# MKV10Z1287 register map
Vendor: Freescale Semiconductor, Inc.; Series: Kinetis_V; File version: 1.6
CPU: CM0PLUS r0p0, little endian, no MPU, no FPU, VTOR, 2 interrupt priority bits
Registers are 32-bit, read-write, reset 0x0 unless marked. A register's access mark holds for its fields unless they carry their own. Offsets are from the block's base; [hi:lo] are bit positions.

## NVIC — Nested Vectored Interrupt Controller
Base 0xE000E100
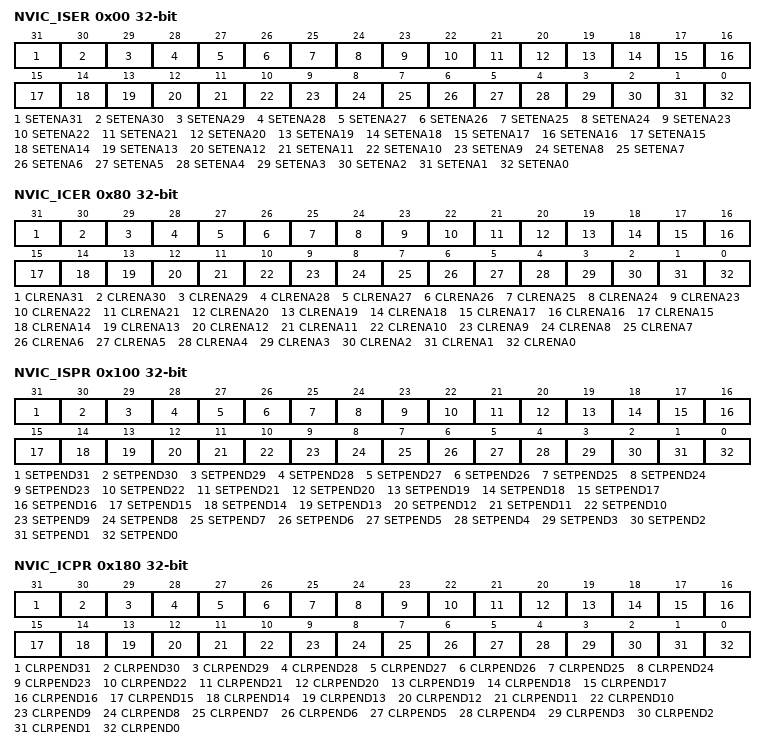
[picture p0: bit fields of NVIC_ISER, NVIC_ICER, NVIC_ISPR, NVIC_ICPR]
0x00 NVIC_ISER — Interrupt Set Enable Register
  [31] SETENA31 — PORTB, PORTC, PORTD and PORTE pin detect interrupt set-enable bit
    0=write: no effect; read: PORTB, PORTC, PORTD and PORTE pin detect interrupt disabled; 1=write: enable PORTB, PORTC, PORTD and PORTE pin detect interrupt; read: PORTB, PORTC, PORTD and PORTE pin detect interrupt enabled
  [30] SETENA30 — PORTA pin detect interrupt set-enable bit
    0=write: no effect; read: PORTA pin detect interrupt disabled; 1=write: enable PORTA pin detect interrupt; read: PORTA pin detect interrupt enabled
  [29] SETENA29 — single interrupt vector for programmable delay block 0 and 1 interrupt set-enable bit
    0=write: no effect; read: single interrupt vector for programmable delay block 0 and 1 interrupt disabled; 1=write: enable single interrupt vector for programmable delay block 0 and 1 interrupt; read: single interrupt vector for programmable delay block 0 and 1 interrupt enabled
  [28] SETENA28 — Low-Power Timer interrupt set-enable bit
    0=write: no effect; read: Low-Power Timer interrupt disabled; 1=write: enable Low-Power Timer interrupt; read: Low-Power Timer interrupt enabled
  [27] SETENA27 — multipurpose clock generator interrupt set-enable bit
    0=write: no effect; read: multipurpose clock generator interrupt disabled; 1=write: enable multipurpose clock generator interrupt; read: multipurpose clock generator interrupt enabled
  [26] SETENA26 — FlexTimer module 5 fault, overflow and channels interrupt set-enable bit
    0=write: no effect; read: FlexTimer module 5 fault, overflow and channels interrupt disabled; 1=write: enable FlexTimer module 5 fault, overflow and channels interrupt; read: FlexTimer module 5 fault, overflow and channels interrupt enabled
  [25] SETENA25 — digital-to-analog converter 0 interrupt set-enable bit
    0=write: no effect; read: digital-to-analog converter 0 interrupt disabled; 1=write: enable digital-to-analog converter 0 interrupt; read: digital-to-analog converter 0 interrupt enabled
  [24] SETENA24 — FlexTimer module 4 fault, overflow and channels interrupt set-enable bit
    0=write: no effect; read: FlexTimer module 4 fault, overflow and channels interrupt disabled; 1=write: enable FlexTimer module 4 fault, overflow and channels interrupt; read: FlexTimer module 4 fault, overflow and channels interrupt enabled
  [23] SETENA23 — single interrupt vector for WDOG and EWM interrupt set-enable bit
    0=write: no effect; read: single interrupt vector for WDOG and EWM interrupt disabled; 1=write: enable single interrupt vector for WDOG and EWM interrupt; read: single interrupt vector for WDOG and EWM interrupt enabled
  [22] SETENA22 — FlexTimer module 3 fault, overflow and channels interrupt set-enable bit
    0=write: no effect; read: FlexTimer module 3 fault, overflow and channels interrupt disabled; 1=write: enable FlexTimer module 3 fault, overflow and channels interrupt; read: FlexTimer module 3 fault, overflow and channels interrupt enabled
  [21] SETENA21 — Comparator 1 interrupt set-enable bit
    0=write: no effect; read: Comparator 1 interrupt disabled; 1=write: enable Comparator 1 interrupt; read: Comparator 1 interrupt enabled
  [20] SETENA20 — Comparator 0 interrupt set-enable bit
    0=write: no effect; read: Comparator 0 interrupt disabled; 1=write: enable Comparator 0 interrupt; read: Comparator 0 interrupt enabled
  [19] SETENA19 — FlexTimer module 2 fault, overflow and channels interrupt set-enable bit
    0=write: no effect; read: FlexTimer module 2 fault, overflow and channels interrupt disabled; 1=write: enable FlexTimer module 2 fault, overflow and channels interrupt; read: FlexTimer module 2 fault, overflow and channels interrupt enabled
  [18] SETENA18 — FlexTimer module 1 fault, overflow and channels interrupt set-enable bit
    0=write: no effect; read: FlexTimer module 1 fault, overflow and channels interrupt disabled; 1=write: enable FlexTimer module 1 fault, overflow and channels interrupt; read: FlexTimer module 1 fault, overflow and channels interrupt enabled
  [17] SETENA17 — FlexTimer module 0 fault, overflow and channels interrupt set-enable bit
    0=write: no effect; read: FlexTimer module 0 fault, overflow and channels interrupt disabled; 1=write: enable FlexTimer module 0 fault, overflow and channels interrupt; read: FlexTimer module 0 fault, overflow and channels interrupt enabled
  [16] SETENA16 — Analog-to-digital converter 1 interrupt set-enable bit
    0=write: no effect; read: Analog-to-digital converter 1 interrupt disabled; 1=write: enable Analog-to-digital converter 1 interrupt; read: Analog-to-digital converter 1 interrupt enabled
  [15] SETENA15 — Analog-to-digital converter 0 interrupt set-enable bit
    0=write: no effect; read: Analog-to-digital converter 0 interrupt disabled; 1=write: enable Analog-to-digital converter 0 interrupt; read: Analog-to-digital converter 0 interrupt enabled
  [14] SETENA14 — Reserved iv 30 interrupt set-enable bit
    0=write: no effect; read: Reserved iv 30 interrupt disabled; 1=write: enable Reserved iv 30 interrupt; read: Reserved iv 30 interrupt enabled
  [13] SETENA13 — UART1 status and error interrupt set-enable bit
    0=write: no effect; read: UART1 status and error interrupt disabled; 1=write: enable UART1 status and error interrupt; read: UART1 status and error interrupt enabled
  [12] SETENA12 — UART0 status and error interrupt set-enable bit
    0=write: no effect; read: UART0 status and error interrupt disabled; 1=write: enable UART0 status and error interrupt; read: UART0 status and error interrupt enabled
  [11] SETENA11 — Reserved iv 27 interrupt set-enable bit
    0=write: no effect; read: Reserved iv 27 interrupt disabled; 1=write: enable Reserved iv 27 interrupt; read: Reserved iv 27 interrupt enabled
  [10] SETENA10 — serial peripheral interface 0 interrupt set-enable bit
    0=write: no effect; read: serial peripheral interface 0 interrupt disabled; 1=write: enable serial peripheral interface 0 interrupt; read: serial peripheral interface 0 interrupt enabled
  [9] SETENA9 — Reserved iv 25 interrupt set-enable bit
    0=write: no effect; read: Reserved iv 25 interrupt disabled; 1=write: enable Reserved iv 25 interrupt; read: Reserved iv 25 interrupt enabled
  [8] SETENA8 — inter-integrated circuit 0 interrupt set-enable bit
    0=write: no effect; read: inter-integrated circuit 0 interrupt disabled; 1=write: enable inter-integrated circuit 0 interrupt; read: inter-integrated circuit 0 interrupt enabled
  [7] SETENA7 — low leakage wakeup interrupt set-enable bit
    0=write: no effect; read: low leakage wakeup interrupt disabled; 1=write: enable low leakage wakeup interrupt; read: low leakage wakeup interrupt enabled
  [6] SETENA6 — low-voltage detect and low-voltage warning interrupt set-enable bit
    0=write: no effect; read: low-voltage detect and low-voltage warning interrupt disabled; 1=write: enable low-voltage detect and low-voltage warning interrupt; read: low-voltage detect and low-voltage warning interrupt enabled
  [5] SETENA5 — FTFA command complete and read collision interrupt set-enable bit
    0=write: no effect; read: FTFA command complete and read collision interrupt disabled; 1=write: enable FTFA command complete and read collision interrupt; read: FTFA command complete and read collision interrupt enabled
  [4] SETENA4 — DMA error interrupt channels 0-7 interrupt set-enable bit
    0=write: no effect; read: DMA error interrupt channels 0-7 interrupt disabled; 1=write: enable DMA error interrupt channels 0-7 interrupt; read: DMA error interrupt channels 0-7 interrupt enabled
  [3] SETENA3 — DMA channel 2 and 7 transfer complete interrupt set-enable bit
    0=write: no effect; read: DMA channel 2 and 7 transfer complete interrupt disabled; 1=write: enable DMA channel 2 and 7 transfer complete interrupt; read: DMA channel 2 and 7 transfer complete interrupt enabled
  [2] SETENA2 — DMA channel 2 and 6 transfer complete interrupt set-enable bit
    0=write: no effect; read: DMA channel 2 and 6 transfer complete interrupt disabled; 1=write: enable DMA channel 2 and 6 transfer complete interrupt; read: DMA channel 2 and 6 transfer complete interrupt enabled
  [1] SETENA1 — DMA channel 1 and 5 transfer complete interrupt set-enable bit
    0=write: no effect; read: DMA channel 1 and 5 transfer complete interrupt disabled; 1=write: enable DMA channel 1 and 5 transfer complete interrupt; read: DMA channel 1 and 5 transfer complete interrupt enabled
  [0] SETENA0 — DMA channel 0 and 4 transfer complete interrupt set-enable bit
    0=write: no effect; read: DMA channel 0 and 4 transfer complete interrupt disabled; 1=write: enable DMA channel 0 and 4 transfer complete interrupt; read: DMA channel 0 and 4 transfer complete interrupt enabled
0x80 NVIC_ICER — Interrupt Clear Enable Register
  [31] CLRENA31 — PORTB, PORTC, PORTD and PORTE pin detect interrupt clear-enable bit
    0=write: no effect; read: PORTB, PORTC, PORTD and PORTE pin detect interrupt disabled; 1=write: disable PORTB, PORTC, PORTD and PORTE pin detect interrupt; read: PORTB, PORTC, PORTD and PORTE pin detect interrupt enabled
  [30] CLRENA30 — PORTA pin detect interrupt clear-enable bit
    0=write: no effect; read: PORTA pin detect interrupt disabled; 1=write: disable PORTA pin detect interrupt; read: PORTA pin detect interrupt enabled
  [29] CLRENA29 — single interrupt vector for programmable delay block 0 and 1 interrupt clear-enable bit
    0=write: no effect; read: single interrupt vector for programmable delay block 0 and 1 interrupt disabled; 1=write: disable single interrupt vector for programmable delay block 0 and 1 interrupt; read: single interrupt vector for programmable delay block 0 and 1 interrupt enabled
  [28] CLRENA28 — Low-Power Timer interrupt clear-enable bit
    0=write: no effect; read: Low-Power Timer interrupt disabled; 1=write: disable Low-Power Timer interrupt; read: Low-Power Timer interrupt enabled
  [27] CLRENA27 — multipurpose clock generator interrupt clear-enable bit
    0=write: no effect; read: multipurpose clock generator interrupt disabled; 1=write: disable multipurpose clock generator interrupt; read: multipurpose clock generator interrupt enabled
  [26] CLRENA26 — FlexTimer module 5 fault, overflow and channels interrupt clear-enable bit
    0=write: no effect; read: FlexTimer module 5 fault, overflow and channels interrupt disabled; 1=write: disable FlexTimer module 5 fault, overflow and channels interrupt; read: FlexTimer module 5 fault, overflow and channels interrupt enabled
  [25] CLRENA25 — digital-to-analog converter 0 interrupt clear-enable bit
    0=write: no effect; read: digital-to-analog converter 0 interrupt disabled; 1=write: disable digital-to-analog converter 0 interrupt; read: digital-to-analog converter 0 interrupt enabled
  [24] CLRENA24 — FlexTimer module 4 fault, overflow and channels interrupt clear-enable bit
    0=write: no effect; read: FlexTimer module 4 fault, overflow and channels interrupt disabled; 1=write: disable FlexTimer module 4 fault, overflow and channels interrupt; read: FlexTimer module 4 fault, overflow and channels interrupt enabled
  [23] CLRENA23 — single interrupt vector for WDOG and EWM interrupt clear-enable bit
    0=write: no effect; read: single interrupt vector for WDOG and EWM interrupt disabled; 1=write: disable single interrupt vector for WDOG and EWM interrupt; read: single interrupt vector for WDOG and EWM interrupt enabled
  [22] CLRENA22 — FlexTimer module 3 fault, overflow and channels interrupt clear-enable bit
    0=write: no effect; read: FlexTimer module 3 fault, overflow and channels interrupt disabled; 1=write: disable FlexTimer module 3 fault, overflow and channels interrupt; read: FlexTimer module 3 fault, overflow and channels interrupt enabled
  [21] CLRENA21 — Comparator 1 interrupt clear-enable bit
    0=write: no effect; read: Comparator 1 interrupt disabled; 1=write: disable Comparator 1 interrupt; read: Comparator 1 interrupt enabled
  [20] CLRENA20 — Comparator 0 interrupt clear-enable bit
    0=write: no effect; read: Comparator 0 interrupt disabled; 1=write: disable Comparator 0 interrupt; read: Comparator 0 interrupt enabled
  [19] CLRENA19 — FlexTimer module 2 fault, overflow and channels interrupt clear-enable bit
    0=write: no effect; read: FlexTimer module 2 fault, overflow and channels interrupt disabled; 1=write: disable FlexTimer module 2 fault, overflow and channels interrupt; read: FlexTimer module 2 fault, overflow and channels interrupt enabled
  [18] CLRENA18 — FlexTimer module 1 fault, overflow and channels interrupt clear-enable bit
    0=write: no effect; read: FlexTimer module 1 fault, overflow and channels interrupt disabled; 1=write: disable FlexTimer module 1 fault, overflow and channels interrupt; read: FlexTimer module 1 fault, overflow and channels interrupt enabled
  [17] CLRENA17 — FlexTimer module 0 fault, overflow and channels interrupt clear-enable bit
    0=write: no effect; read: FlexTimer module 0 fault, overflow and channels interrupt disabled; 1=write: disable FlexTimer module 0 fault, overflow and channels interrupt; read: FlexTimer module 0 fault, overflow and channels interrupt enabled
  [16] CLRENA16 — Analog-to-digital converter 1 interrupt clear-enable bit
    0=write: no effect; read: Analog-to-digital converter 1 interrupt disabled; 1=write: disable Analog-to-digital converter 1 interrupt; read: Analog-to-digital converter 1 interrupt enabled
  [15] CLRENA15 — Analog-to-digital converter 0 interrupt clear-enable bit
    0=write: no effect; read: Analog-to-digital converter 0 interrupt disabled; 1=write: disable Analog-to-digital converter 0 interrupt; read: Analog-to-digital converter 0 interrupt enabled
  [14] CLRENA14 — Reserved iv 30 interrupt clear-enable bit
    0=write: no effect; read: Reserved iv 30 interrupt disabled; 1=write: disable Reserved iv 30 interrupt; read: Reserved iv 30 interrupt enabled
  [13] CLRENA13 — UART1 status and error interrupt clear-enable bit
    0=write: no effect; read: UART1 status and error interrupt disabled; 1=write: disable UART1 status and error interrupt; read: UART1 status and error interrupt enabled
  [12] CLRENA12 — UART0 status and error interrupt clear-enable bit
    0=write: no effect; read: UART0 status and error interrupt disabled; 1=write: disable UART0 status and error interrupt; read: UART0 status and error interrupt enabled
  [11] CLRENA11 — Reserved iv 27 interrupt clear-enable bit
    0=write: no effect; read: Reserved iv 27 interrupt disabled; 1=write: disable Reserved iv 27 interrupt; read: Reserved iv 27 interrupt enabled
  [10] CLRENA10 — serial peripheral interface 0 interrupt clear-enable bit
    0=write: no effect; read: serial peripheral interface 0 interrupt disabled; 1=write: disable serial peripheral interface 0 interrupt; read: serial peripheral interface 0 interrupt enabled
  [9] CLRENA9 — Reserved iv 25 interrupt clear-enable bit
    0=write: no effect; read: Reserved iv 25 interrupt disabled; 1=write: disable Reserved iv 25 interrupt; read: Reserved iv 25 interrupt enabled
  [8] CLRENA8 — inter-integrated circuit 0 interrupt clear-enable bit
    0=write: no effect; read: inter-integrated circuit 0 interrupt disabled; 1=write: disable inter-integrated circuit 0 interrupt; read: inter-integrated circuit 0 interrupt enabled
  [7] CLRENA7 — low leakage wakeup interrupt clear-enable bit
    0=write: no effect; read: low leakage wakeup interrupt disabled; 1=write: disable low leakage wakeup interrupt; read: low leakage wakeup interrupt enabled
  [6] CLRENA6 — low-voltage detect and low-voltage warning interrupt clear-enable bit
    0=write: no effect; read: low-voltage detect and low-voltage warning interrupt disabled; 1=write: disable low-voltage detect and low-voltage warning interrupt; read: low-voltage detect and low-voltage warning interrupt enabled
  [5] CLRENA5 — FTFA command complete and read collision interrupt clear-enable bit
    0=write: no effect; read: FTFA command complete and read collision interrupt disabled; 1=write: disable FTFA command complete and read collision interrupt; read: FTFA command complete and read collision interrupt enabled
  [4] CLRENA4 — DMA error interrupt channels 0-7 interrupt clear-enable bit
    0=write: no effect; read: DMA error interrupt channels 0-7 interrupt disabled; 1=write: disable DMA error interrupt channels 0-7 interrupt; read: DMA error interrupt channels 0-7 interrupt enabled
  [3] CLRENA3 — DMA channel 2 and 7 transfer complete interrupt clear-enable bit
    0=write: no effect; read: DMA channel 2 and 7 transfer complete interrupt disabled; 1=write: disable DMA channel 2 and 7 transfer complete interrupt; read: DMA channel 2 and 7 transfer complete interrupt enabled
  [2] CLRENA2 — DMA channel 2 and 6 transfer complete interrupt clear-enable bit
    0=write: no effect; read: DMA channel 2 and 6 transfer complete interrupt disabled; 1=write: disable DMA channel 2 and 6 transfer complete interrupt; read: DMA channel 2 and 6 transfer complete interrupt enabled
  [1] CLRENA1 — DMA channel 1 and 5 transfer complete interrupt clear-enable bit
    0=write: no effect; read: DMA channel 1 and 5 transfer complete interrupt disabled; 1=write: disable DMA channel 1 and 5 transfer complete interrupt; read: DMA channel 1 and 5 transfer complete interrupt enabled
  [0] CLRENA0 — DMA channel 0 and 4 transfer complete interrupt clear-enable bit
    0=write: no effect; read: DMA channel 0 and 4 transfer complete interrupt disabled; 1=write: disable DMA channel 0 and 4 transfer complete interrupt; read: DMA channel 0 and 4 transfer complete interrupt enabled
0x100 NVIC_ISPR — Interrupt Set Pending Register
  [31] SETPEND31 — PORTB, PORTC, PORTD and PORTE pin detect interrupt set-pending bit
    0=write: no effect; read: PORTB, PORTC, PORTD and PORTE pin detect interrupt is not pending; 1=write: changes the PORTB, PORTC, PORTD and PORTE pin detect interrupt state to pending; read: PORTB, PORTC, PORTD and PORTE pin detect interrupt is pending
  [30] SETPEND30 — PORTA pin detect interrupt set-pending bit
    0=write: no effect; read: PORTA pin detect interrupt is not pending; 1=write: changes the PORTA pin detect interrupt state to pending; read: PORTA pin detect interrupt is pending
  [29] SETPEND29 — single interrupt vector for programmable delay block 0 and 1 interrupt set-pending bit
    0=write: no effect; read: single interrupt vector for programmable delay block 0 and 1 interrupt is not pending; 1=write: changes the single interrupt vector for programmable delay block 0 and 1 interrupt state to pending; read: single interrupt vector for programmable delay block 0 and 1 interrupt is pending
  [28] SETPEND28 — Low-Power Timer interrupt set-pending bit
    0=write: no effect; read: Low-Power Timer interrupt is not pending; 1=write: changes the Low-Power Timer interrupt state to pending; read: Low-Power Timer interrupt is pending
  [27] SETPEND27 — multipurpose clock generator interrupt set-pending bit
    0=write: no effect; read: multipurpose clock generator interrupt is not pending; 1=write: changes the multipurpose clock generator interrupt state to pending; read: multipurpose clock generator interrupt is pending
  [26] SETPEND26 — FlexTimer module 5 fault, overflow and channels interrupt set-pending bit
    0=write: no effect; read: FlexTimer module 5 fault, overflow and channels interrupt is not pending; 1=write: changes the FlexTimer module 5 fault, overflow and channels interrupt state to pending; read: FlexTimer module 5 fault, overflow and channels interrupt is pending
  [25] SETPEND25 — digital-to-analog converter 0 interrupt set-pending bit
    0=write: no effect; read: digital-to-analog converter 0 interrupt is not pending; 1=write: changes the digital-to-analog converter 0 interrupt state to pending; read: digital-to-analog converter 0 interrupt is pending
  [24] SETPEND24 — FlexTimer module 4 fault, overflow and channels interrupt set-pending bit
    0=write: no effect; read: FlexTimer module 4 fault, overflow and channels interrupt is not pending; 1=write: changes the FlexTimer module 4 fault, overflow and channels interrupt state to pending; read: FlexTimer module 4 fault, overflow and channels interrupt is pending
  [23] SETPEND23 — single interrupt vector for WDOG and EWM interrupt set-pending bit
    0=write: no effect; read: single interrupt vector for WDOG and EWM interrupt is not pending; 1=write: changes the single interrupt vector for WDOG and EWM interrupt state to pending; read: single interrupt vector for WDOG and EWM interrupt is pending
  [22] SETPEND22 — FlexTimer module 3 fault, overflow and channels interrupt set-pending bit
    0=write: no effect; read: FlexTimer module 3 fault, overflow and channels interrupt is not pending; 1=write: changes the FlexTimer module 3 fault, overflow and channels interrupt state to pending; read: FlexTimer module 3 fault, overflow and channels interrupt is pending
  [21] SETPEND21 — Comparator 1 interrupt set-pending bit
    0=write: no effect; read: Comparator 1 interrupt is not pending; 1=write: changes the Comparator 1 interrupt state to pending; read: Comparator 1 interrupt is pending
  [20] SETPEND20 — Comparator 0 interrupt set-pending bit
    0=write: no effect; read: Comparator 0 interrupt is not pending; 1=write: changes the Comparator 0 interrupt state to pending; read: Comparator 0 interrupt is pending
  [19] SETPEND19 — FlexTimer module 2 fault, overflow and channels interrupt set-pending bit
    0=write: no effect; read: FlexTimer module 2 fault, overflow and channels interrupt is not pending; 1=write: changes the FlexTimer module 2 fault, overflow and channels interrupt state to pending; read: FlexTimer module 2 fault, overflow and channels interrupt is pending
  [18] SETPEND18 — FlexTimer module 1 fault, overflow and channels interrupt set-pending bit
    0=write: no effect; read: FlexTimer module 1 fault, overflow and channels interrupt is not pending; 1=write: changes the FlexTimer module 1 fault, overflow and channels interrupt state to pending; read: FlexTimer module 1 fault, overflow and channels interrupt is pending
  [17] SETPEND17 — FlexTimer module 0 fault, overflow and channels interrupt set-pending bit
    0=write: no effect; read: FlexTimer module 0 fault, overflow and channels interrupt is not pending; 1=write: changes the FlexTimer module 0 fault, overflow and channels interrupt state to pending; read: FlexTimer module 0 fault, overflow and channels interrupt is pending
  [16] SETPEND16 — Analog-to-digital converter 1 interrupt set-pending bit
    0=write: no effect; read: Analog-to-digital converter 1 interrupt is not pending; 1=write: changes the Analog-to-digital converter 1 interrupt state to pending; read: Analog-to-digital converter 1 interrupt is pending
  [15] SETPEND15 — Analog-to-digital converter 0 interrupt set-pending bit
    0=write: no effect; read: Analog-to-digital converter 0 interrupt is not pending; 1=write: changes the Analog-to-digital converter 0 interrupt state to pending; read: Analog-to-digital converter 0 interrupt is pending
  [14] SETPEND14 — Reserved iv 30 interrupt set-pending bit
    0=write: no effect; read: Reserved iv 30 interrupt is not pending; 1=write: changes the Reserved iv 30 interrupt state to pending; read: Reserved iv 30 interrupt is pending
  [13] SETPEND13 — UART1 status and error interrupt set-pending bit
    0=write: no effect; read: UART1 status and error interrupt is not pending; 1=write: changes the UART1 status and error interrupt state to pending; read: UART1 status and error interrupt is pending
  [12] SETPEND12 — UART0 status and error interrupt set-pending bit
    0=write: no effect; read: UART0 status and error interrupt is not pending; 1=write: changes the UART0 status and error interrupt state to pending; read: UART0 status and error interrupt is pending
  [11] SETPEND11 — Reserved iv 27 interrupt set-pending bit
    0=write: no effect; read: Reserved iv 27 interrupt is not pending; 1=write: changes the Reserved iv 27 interrupt state to pending; read: Reserved iv 27 interrupt is pending
  [10] SETPEND10 — serial peripheral interface 0 interrupt set-pending bit
    0=write: no effect; read: serial peripheral interface 0 interrupt is not pending; 1=write: changes the serial peripheral interface 0 interrupt state to pending; read: serial peripheral interface 0 interrupt is pending
  [9] SETPEND9 — Reserved iv 25 interrupt set-pending bit
    0=write: no effect; read: Reserved iv 25 interrupt is not pending; 1=write: changes the Reserved iv 25 interrupt state to pending; read: Reserved iv 25 interrupt is pending
  [8] SETPEND8 — inter-integrated circuit 0 interrupt set-pending bit
    0=write: no effect; read: inter-integrated circuit 0 interrupt is not pending; 1=write: changes the inter-integrated circuit 0 interrupt state to pending; read: inter-integrated circuit 0 interrupt is pending
  [7] SETPEND7 — low leakage wakeup interrupt set-pending bit
    0=write: no effect; read: low leakage wakeup interrupt is not pending; 1=write: changes the low leakage wakeup interrupt state to pending; read: low leakage wakeup interrupt is pending
  [6] SETPEND6 — low-voltage detect and low-voltage warning interrupt set-pending bit
    0=write: no effect; read: low-voltage detect and low-voltage warning interrupt is not pending; 1=write: changes the low-voltage detect and low-voltage warning interrupt state to pending; read: low-voltage detect and low-voltage warning interrupt is pending
  [5] SETPEND5 — FTFA command complete and read collision interrupt set-pending bit
    0=write: no effect; read: FTFA command complete and read collision interrupt is not pending; 1=write: changes the FTFA command complete and read collision interrupt state to pending; read: FTFA command complete and read collision interrupt is pending
  [4] SETPEND4 — DMA error interrupt channels 0-7 interrupt set-pending bit
    0=write: no effect; read: DMA error interrupt channels 0-7 interrupt is not pending; 1=write: changes the DMA error interrupt channels 0-7 interrupt state to pending; read: DMA error interrupt channels 0-7 interrupt is pending
  [3] SETPEND3 — DMA channel 2 and 7 transfer complete interrupt set-pending bit
    0=write: no effect; read: DMA channel 2 and 7 transfer complete interrupt is not pending; 1=write: changes the DMA channel 2 and 7 transfer complete interrupt state to pending; read: DMA channel 2 and 7 transfer complete interrupt is pending
  [2] SETPEND2 — DMA channel 2 and 6 transfer complete interrupt set-pending bit
    0=write: no effect; read: DMA channel 2 and 6 transfer complete interrupt is not pending; 1=write: changes the DMA channel 2 and 6 transfer complete interrupt state to pending; read: DMA channel 2 and 6 transfer complete interrupt is pending
  [1] SETPEND1 — DMA channel 1 and 5 transfer complete interrupt set-pending bit
    0=write: no effect; read: DMA channel 1 and 5 transfer complete interrupt is not pending; 1=write: changes the DMA channel 1 and 5 transfer complete interrupt state to pending; read: DMA channel 1 and 5 transfer complete interrupt is pending
  [0] SETPEND0 — DMA channel 0 and 4 transfer complete interrupt set-pending bit
    0=write: no effect; read: DMA channel 0 and 4 transfer complete interrupt is not pending; 1=write: changes the DMA channel 0 and 4 transfer complete interrupt state to pending; read: DMA channel 0 and 4 transfer complete interrupt is pending
0x180 NVIC_ICPR — Interrupt Clear Pending Register
  [31] CLRPEND31 — PORTB, PORTC, PORTD and PORTE pin detect interrupt clear-pending bit
    0=write: no effect; read: PORTB, PORTC, PORTD and PORTE pin detect interrupt is not pending; 1=write: removes pending state from the PORTB, PORTC, PORTD and PORTE pin detect interrupt; read: PORTB, PORTC, PORTD and PORTE pin detect interrupt is pending
  [30] CLRPEND30 — PORTA pin detect interrupt clear-pending bit
    0=write: no effect; read: PORTA pin detect interrupt is not pending; 1=write: removes pending state from the PORTA pin detect interrupt; read: PORTA pin detect interrupt is pending
  [29] CLRPEND29 — single interrupt vector for programmable delay block 0 and 1 interrupt clear-pending bit
    0=write: no effect; read: single interrupt vector for programmable delay block 0 and 1 interrupt is not pending; 1=write: removes pending state from the single interrupt vector for programmable delay block 0 and 1 interrupt; read: single interrupt vector for programmable delay block 0 and 1 interrupt is pending
  [28] CLRPEND28 — Low-Power Timer interrupt clear-pending bit
    0=write: no effect; read: Low-Power Timer interrupt is not pending; 1=write: removes pending state from the Low-Power Timer interrupt; read: Low-Power Timer interrupt is pending
  [27] CLRPEND27 — multipurpose clock generator interrupt clear-pending bit
    0=write: no effect; read: multipurpose clock generator interrupt is not pending; 1=write: removes pending state from the multipurpose clock generator interrupt; read: multipurpose clock generator interrupt is pending
  [26] CLRPEND26 — FlexTimer module 5 fault, overflow and channels interrupt clear-pending bit
    0=write: no effect; read: FlexTimer module 5 fault, overflow and channels interrupt is not pending; 1=write: removes pending state from the FlexTimer module 5 fault, overflow and channels interrupt; read: FlexTimer module 5 fault, overflow and channels interrupt is pending
  [25] CLRPEND25 — digital-to-analog converter 0 interrupt clear-pending bit
    0=write: no effect; read: digital-to-analog converter 0 interrupt is not pending; 1=write: removes pending state from the digital-to-analog converter 0 interrupt; read: digital-to-analog converter 0 interrupt is pending
  [24] CLRPEND24 — FlexTimer module 4 fault, overflow and channels interrupt clear-pending bit
    0=write: no effect; read: FlexTimer module 4 fault, overflow and channels interrupt is not pending; 1=write: removes pending state from the FlexTimer module 4 fault, overflow and channels interrupt; read: FlexTimer module 4 fault, overflow and channels interrupt is pending
  [23] CLRPEND23 — single interrupt vector for WDOG and EWM interrupt clear-pending bit
    0=write: no effect; read: single interrupt vector for WDOG and EWM interrupt is not pending; 1=write: removes pending state from the single interrupt vector for WDOG and EWM interrupt; read: single interrupt vector for WDOG and EWM interrupt is pending
  [22] CLRPEND22 — FlexTimer module 3 fault, overflow and channels interrupt clear-pending bit
    0=write: no effect; read: FlexTimer module 3 fault, overflow and channels interrupt is not pending; 1=write: removes pending state from the FlexTimer module 3 fault, overflow and channels interrupt; read: FlexTimer module 3 fault, overflow and channels interrupt is pending
  [21] CLRPEND21 — Comparator 1 interrupt clear-pending bit
    0=write: no effect; read: Comparator 1 interrupt is not pending; 1=write: removes pending state from the Comparator 1 interrupt; read: Comparator 1 interrupt is pending
  [20] CLRPEND20 — Comparator 0 interrupt clear-pending bit
    0=write: no effect; read: Comparator 0 interrupt is not pending; 1=write: removes pending state from the Comparator 0 interrupt; read: Comparator 0 interrupt is pending
  [19] CLRPEND19 — FlexTimer module 2 fault, overflow and channels interrupt clear-pending bit
    0=write: no effect; read: FlexTimer module 2 fault, overflow and channels interrupt is not pending; 1=write: removes pending state from the FlexTimer module 2 fault, overflow and channels interrupt; read: FlexTimer module 2 fault, overflow and channels interrupt is pending
  [18] CLRPEND18 — FlexTimer module 1 fault, overflow and channels interrupt clear-pending bit
    0=write: no effect; read: FlexTimer module 1 fault, overflow and channels interrupt is not pending; 1=write: removes pending state from the FlexTimer module 1 fault, overflow and channels interrupt; read: FlexTimer module 1 fault, overflow and channels interrupt is pending
  [17] CLRPEND17 — FlexTimer module 0 fault, overflow and channels interrupt clear-pending bit
    0=write: no effect; read: FlexTimer module 0 fault, overflow and channels interrupt is not pending; 1=write: removes pending state from the FlexTimer module 0 fault, overflow and channels interrupt; read: FlexTimer module 0 fault, overflow and channels interrupt is pending
  [16] CLRPEND16 — Analog-to-digital converter 1 interrupt clear-pending bit
    0=write: no effect; read: Analog-to-digital converter 1 interrupt is not pending; 1=write: removes pending state from the Analog-to-digital converter 1 interrupt; read: Analog-to-digital converter 1 interrupt is pending
  [15] CLRPEND15 — Analog-to-digital converter 0 interrupt clear-pending bit
    0=write: no effect; read: Analog-to-digital converter 0 interrupt is not pending; 1=write: removes pending state from the Analog-to-digital converter 0 interrupt; read: Analog-to-digital converter 0 interrupt is pending
  [14] CLRPEND14 — Reserved iv 30 interrupt clear-pending bit
    0=write: no effect; read: Reserved iv 30 interrupt is not pending; 1=write: removes pending state from the Reserved iv 30 interrupt; read: Reserved iv 30 interrupt is pending
  [13] CLRPEND13 — UART1 status and error interrupt clear-pending bit
    0=write: no effect; read: UART1 status and error interrupt is not pending; 1=write: removes pending state from the UART1 status and error interrupt; read: UART1 status and error interrupt is pending
  [12] CLRPEND12 — UART0 status and error interrupt clear-pending bit
    0=write: no effect; read: UART0 status and error interrupt is not pending; 1=write: removes pending state from the UART0 status and error interrupt; read: UART0 status and error interrupt is pending
  [11] CLRPEND11 — Reserved iv 27 interrupt clear-pending bit
    0=write: no effect; read: Reserved iv 27 interrupt is not pending; 1=write: removes pending state from the Reserved iv 27 interrupt; read: Reserved iv 27 interrupt is pending
  [10] CLRPEND10 — serial peripheral interface 0 interrupt clear-pending bit
    0=write: no effect; read: serial peripheral interface 0 interrupt is not pending; 1=write: removes pending state from the serial peripheral interface 0 interrupt; read: serial peripheral interface 0 interrupt is pending
  [9] CLRPEND9 — Reserved iv 25 interrupt clear-pending bit
    0=write: no effect; read: Reserved iv 25 interrupt is not pending; 1=write: removes pending state from the Reserved iv 25 interrupt; read: Reserved iv 25 interrupt is pending
  [8] CLRPEND8 — inter-integrated circuit 0 interrupt clear-pending bit
    0=write: no effect; read: inter-integrated circuit 0 interrupt is not pending; 1=write: removes pending state from the inter-integrated circuit 0 interrupt; read: inter-integrated circuit 0 interrupt is pending
  [7] CLRPEND7 — low leakage wakeup interrupt clear-pending bit
    0=write: no effect; read: low leakage wakeup interrupt is not pending; 1=write: removes pending state from the low leakage wakeup interrupt; read: low leakage wakeup interrupt is pending
  [6] CLRPEND6 — low-voltage detect and low-voltage warning interrupt clear-pending bit
    0=write: no effect; read: low-voltage detect and low-voltage warning interrupt is not pending; 1=write: removes pending state from the low-voltage detect and low-voltage warning interrupt; read: low-voltage detect and low-voltage warning interrupt is pending
  [5] CLRPEND5 — FTFA command complete and read collision interrupt clear-pending bit
    0=write: no effect; read: FTFA command complete and read collision interrupt is not pending; 1=write: removes pending state from the FTFA command complete and read collision interrupt; read: FTFA command complete and read collision interrupt is pending
  [4] CLRPEND4 — DMA error interrupt channels 0-7 interrupt clear-pending bit
    0=write: no effect; read: DMA error interrupt channels 0-7 interrupt is not pending; 1=write: removes pending state from the DMA error interrupt channels 0-7 interrupt; read: DMA error interrupt channels 0-7 interrupt is pending
  [3] CLRPEND3 — DMA channel 2 and 7 transfer complete interrupt clear-pending bit
    0=write: no effect; read: DMA channel 2 and 7 transfer complete interrupt is not pending; 1=write: removes pending state from the DMA channel 2 and 7 transfer complete interrupt; read: DMA channel 2 and 7 transfer complete interrupt is pending
  [2] CLRPEND2 — DMA channel 2 and 6 transfer complete interrupt clear-pending bit
    0=write: no effect; read: DMA channel 2 and 6 transfer complete interrupt is not pending; 1=write: removes pending state from the DMA channel 2 and 6 transfer complete interrupt; read: DMA channel 2 and 6 transfer complete interrupt is pending
  [1] CLRPEND1 — DMA channel 1 and 5 transfer complete interrupt clear-pending bit
    0=write: no effect; read: DMA channel 1 and 5 transfer complete interrupt is not pending; 1=write: removes pending state from the DMA channel 1 and 5 transfer complete interrupt; read: DMA channel 1 and 5 transfer complete interrupt is pending
  [0] CLRPEND0 — DMA channel 0 and 4 transfer complete interrupt clear-pending bit
    0=write: no effect; read: DMA channel 0 and 4 transfer complete interrupt is not pending; 1=write: removes pending state from the DMA channel 0 and 4 transfer complete interrupt; read: DMA channel 0 and 4 transfer complete interrupt is pending
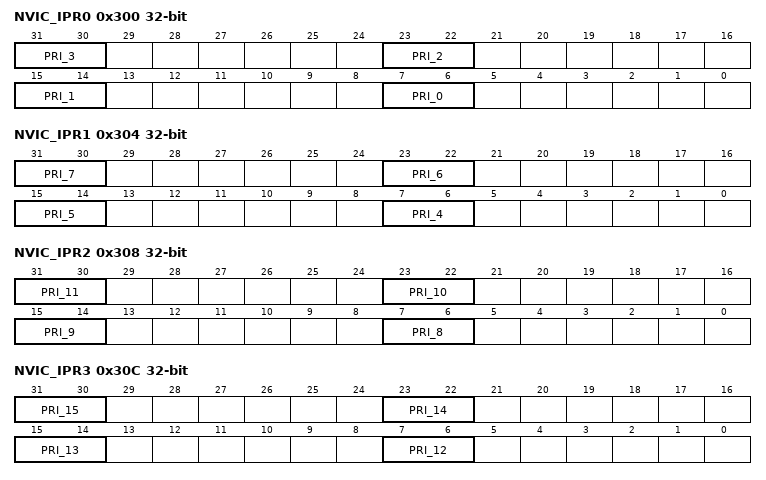
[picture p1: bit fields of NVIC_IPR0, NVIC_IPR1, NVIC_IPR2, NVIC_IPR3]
0x300 NVIC_IPR0 — Interrupt Priority Register 0
  [31:30] PRI_3 — Priority of the DMA channel 2 and 7 transfer complete interrupt
  [23:22] PRI_2 — Priority of the DMA channel 2 and 6 transfer complete interrupt
  [15:14] PRI_1 — Priority of the DMA channel 1 and 5 transfer complete interrupt
  [7:6] PRI_0 — Priority of the DMA channel 0 and 4 transfer complete interrupt
0x304 NVIC_IPR1 — Interrupt Priority Register 1
  [31:30] PRI_7 — Priority of the low leakage wakeup interrupt
  [23:22] PRI_6 — Priority of the low-voltage detect and low-voltage warning interrupt
  [15:14] PRI_5 — Priority of the FTFA command complete and read collision interrupt
  [7:6] PRI_4 — Priority of the DMA error interrupt channels 0-7 interrupt
0x308 NVIC_IPR2 — Interrupt Priority Register 2
  [31:30] PRI_11 — Priority of the Reserved iv 27 interrupt
  [23:22] PRI_10 — Priority of the serial peripheral interface 0 interrupt
  [15:14] PRI_9 — Priority of the Reserved iv 25 interrupt
  [7:6] PRI_8 — Priority of the inter-integrated circuit 0 interrupt
0x30C NVIC_IPR3 — Interrupt Priority Register 3
  [31:30] PRI_15 — Priority of the Analog-to-digital converter 0 interrupt
  [23:22] PRI_14 — Priority of the Reserved iv 30 interrupt
  [15:14] PRI_13 — Priority of the UART1 status and error interrupt
  [7:6] PRI_12 — Priority of the UART0 status and error interrupt
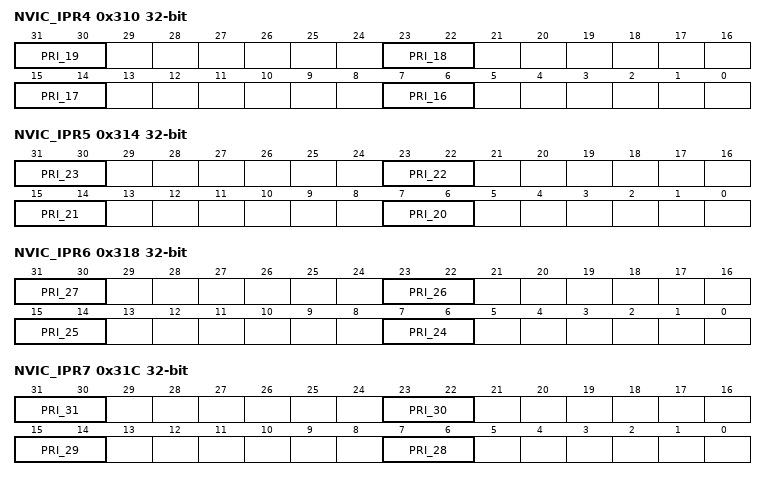
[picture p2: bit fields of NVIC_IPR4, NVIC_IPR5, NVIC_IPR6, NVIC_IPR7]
0x310 NVIC_IPR4 — Interrupt Priority Register 4
  [31:30] PRI_19 — Priority of the FlexTimer module 2 fault, overflow and channels interrupt
  [23:22] PRI_18 — Priority of the FlexTimer module 1 fault, overflow and channels interrupt
  [15:14] PRI_17 — Priority of the FlexTimer module 0 fault, overflow and channels interrupt
  [7:6] PRI_16 — Priority of the Analog-to-digital converter 1 interrupt
0x314 NVIC_IPR5 — Interrupt Priority Register 5
  [31:30] PRI_23 — Priority of the single interrupt vector for WDOG and EWM interrupt
  [23:22] PRI_22 — Priority of the FlexTimer module 3 fault, overflow and channels interrupt
  [15:14] PRI_21 — Priority of the Comparator 1 interrupt
  [7:6] PRI_20 — Priority of the Comparator 0 interrupt
0x318 NVIC_IPR6 — Interrupt Priority Register 6
  [31:30] PRI_27 — Priority of the multipurpose clock generator interrupt
  [23:22] PRI_26 — Priority of the FlexTimer module 5 fault, overflow and channels interrupt
  [15:14] PRI_25 — Priority of the digital-to-analog converter 0 interrupt
  [7:6] PRI_24 — Priority of the FlexTimer module 4 fault, overflow and channels interrupt
0x31C NVIC_IPR7 — Interrupt Priority Register 7
  [31:30] PRI_31 — Priority of the PORTB, PORTC, PORTD and PORTE pin detect interrupt
  [23:22] PRI_30 — Priority of the PORTA pin detect interrupt
  [15:14] PRI_29 — Priority of the single interrupt vector for programmable delay block 0 and 1 interrupt
  [7:6] PRI_28 — Priority of the Low-Power Timer interrupt
